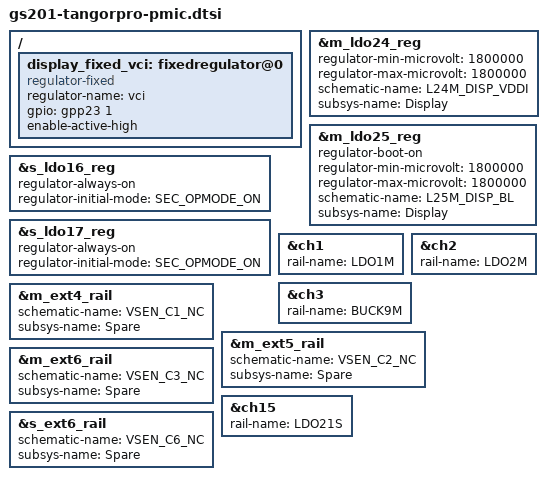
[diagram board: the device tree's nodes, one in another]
// SPDX-License-Identifier: GPL-2.0-only
/*
 * Tangorpro-specific PMIC settings
 *
 * Copyright 2022 Google LLC.
 *
 */

/* Display: vddi-supply voltage */
&m_ldo24_reg {
	regulator-min-microvolt = <1800000>;
	regulator-max-microvolt = <1800000>;
	schematic-name = "L24M_DISP_VDDI";
	subsys-name = "Display";
};

/* Display: vci-supply voltage */
/ {
	display_fixed_vci: fixedregulator@0 {
		compatible = "regulator-fixed";
		regulator-name = "vci";
		gpio = <&gpp23 1 GPIO_ACTIVE_HIGH>;
		enable-active-high;
	};
};

/* Display: backlight enable */
&m_ldo25_reg {
	regulator-boot-on;
	/delete-property/ regulator-always-on;
	regulator-min-microvolt = <1800000>;
	regulator-max-microvolt = <1800000>;
	schematic-name = "L25M_DISP_BL";
	subsys-name = "Display";
};

/* UWB: Ravenclaw and Tangorpro use LDO[16,17]S for UWB */
&s_ldo16_reg {
	regulator-always-on;
	regulator-initial-mode = <SEC_OPMODE_ON>;
};

/* UWB: Ravenclaw and Tangorpro use LDO[16,17]S for UWB */
&s_ldo17_reg {
	regulator-always-on;
	regulator-initial-mode = <SEC_OPMODE_ON>;
};

/* No modem on Tangor Pro */
/* replace VSYS_PWR_MMWAVE to L1M_ALIVE */
&ch1 {
	rail-name = "LDO1M";
};

/* replace VSYS_PWR_MODEM to L2M_ALIVE */
&ch2 {
	rail-name = "LDO2M";
};

/* replace VSYS_PWR_RFFE to S9M_LLDO3 */
&ch3 {
	rail-name = "BUCK9M";
};

&m_ext4_rail {
	schematic-name = "VSEN_C1_NC";
	subsys-name = "Spare";
};

&m_ext5_rail {
	schematic-name = "VSEN_C2_NC";
	subsys-name = "Spare";
};

&m_ext6_rail {
	schematic-name = "VSEN_C3_NC";
	subsys-name = "Spare";
};

/* replace VSYS_PWR_CAM to L21S_VDD2L_MEM */
&ch15 {
	rail-name = "LDO21S";
};

&s_ext6_rail {
	schematic-name = "VSEN_C6_NC";
	subsys-name = "Spare";
};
